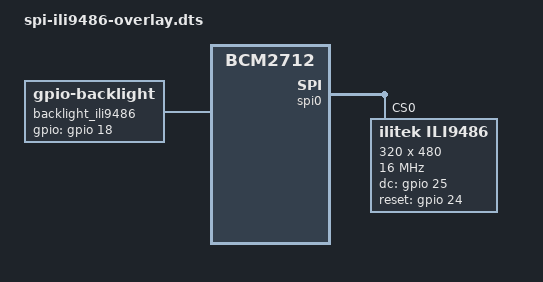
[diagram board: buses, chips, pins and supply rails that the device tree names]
// Raspberry Pi 5 - ILI9486/9488 3.5" SPI Display
// Device Tree Overlays for 3.5" TFT displays
// Copyright (C) 2025 The Android Open Source Project

/dts-v1/;
/plugin/;

// ============================================================================
// ILI9486 3.5" TFT Display (320x480)
// ============================================================================
/ {
    compatible = "brcm,bcm2712";
    
    fragment@0 {
        target = <&spi0>;
        __overlay__ {
            status = "okay";
            #address-cells = <1>;
            #size-cells = <0>;
            
            ili9486: ili9486@0 {
                compatible = "ilitek,ili9486";
                reg = <0>;
                spi-max-frequency = <16000000>;
                
                dc-gpios = <&gpio 25 0>;
                reset-gpios = <&gpio 24 0>;
                
                width = <320>;
                height = <480>;
                buswidth = <8>;
                rotate = <90>;
                fps = <30>;
                bgr;
            };
        };
    };
    
    fragment@1 {
        target = <&gpio>;
        __overlay__ {
            ili9486_pins: ili9486_pins {
                brcm,pins = <24 25 18>;
                brcm,function = <1 1 1>;
            };
        };
    };
    
    fragment@2 {
        target-path = "/";
        __overlay__ {
            backlight_ili9486: backlight {
                compatible = "gpio-backlight";
                gpios = <&gpio 18 0>;
                default-on;
            };
        };
    };
};
